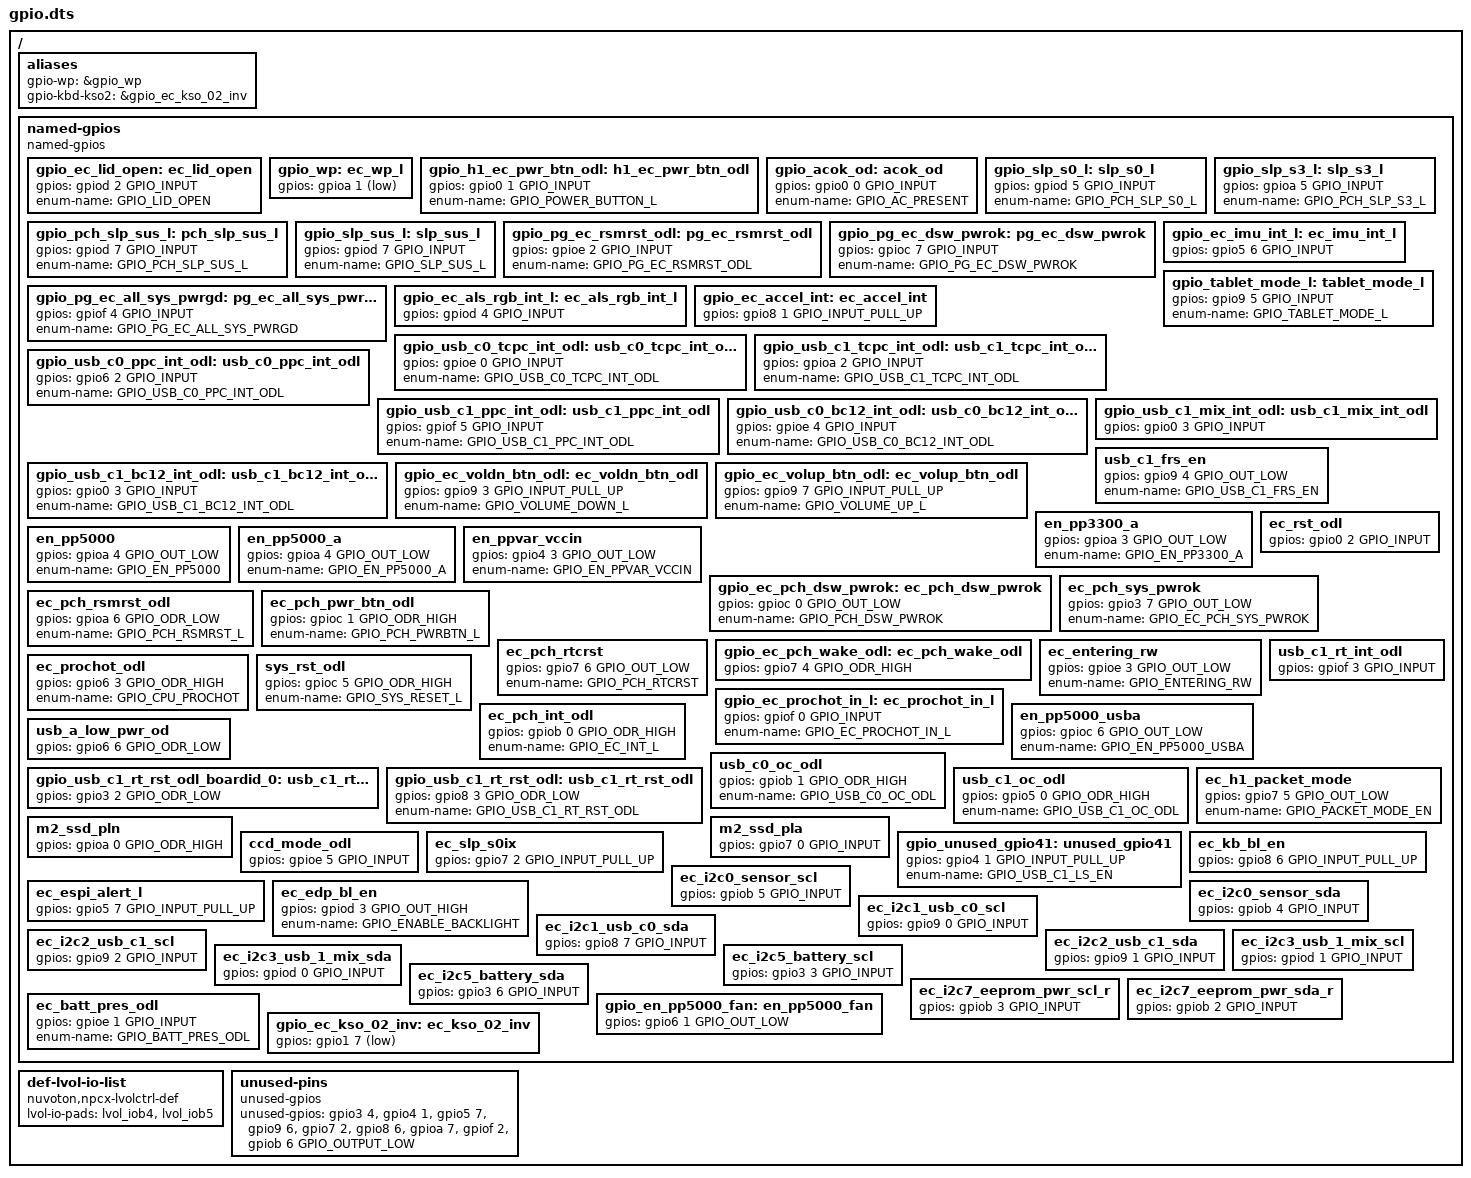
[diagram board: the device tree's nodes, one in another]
/* Copyright 2021 The Chromium OS Authors. All rights reserved.
 * Use of this source code is governed by a BSD-style license that can be
 * found in the LICENSE file.
 */

/ {
	aliases {
		gpio-wp = &gpio_wp;
		gpio-kbd-kso2 = &gpio_ec_kso_02_inv;
	};

	named-gpios {
		compatible = "named-gpios";

		gpio_ec_lid_open: ec_lid_open {
			gpios = <&gpiod 2 GPIO_INPUT>;
			enum-name = "GPIO_LID_OPEN";
		};
		gpio_wp: ec_wp_l {
			gpios = <&gpioa 1 (GPIO_INPUT | GPIO_ACTIVE_LOW)>;
		};
		gpio_h1_ec_pwr_btn_odl: h1_ec_pwr_btn_odl {
			gpios = <&gpio0 1 GPIO_INPUT>;
			enum-name = "GPIO_POWER_BUTTON_L";
		};
		gpio_acok_od: acok_od {
			gpios = <&gpio0 0 GPIO_INPUT>;
			enum-name = "GPIO_AC_PRESENT";
		};
		gpio_slp_s0_l: slp_s0_l {
			gpios = <&gpiod 5 GPIO_INPUT>;
			enum-name = "GPIO_PCH_SLP_S0_L";
		};
		gpio_slp_s3_l: slp_s3_l {
			gpios = <&gpioa 5 GPIO_INPUT>;
			enum-name = "GPIO_PCH_SLP_S3_L";
		};
		gpio_pch_slp_sus_l: pch_slp_sus_l {
			gpios = <&gpiod 7 GPIO_INPUT>;
			enum-name = "GPIO_PCH_SLP_SUS_L";
		};
		gpio_slp_sus_l: slp_sus_l {
			gpios = <&gpiod 7 GPIO_INPUT>;
			enum-name = "GPIO_SLP_SUS_L";
		};
		gpio_pg_ec_rsmrst_odl: pg_ec_rsmrst_odl {
			gpios = <&gpioe 2 GPIO_INPUT>;
			enum-name = "GPIO_PG_EC_RSMRST_ODL";
		};
		gpio_pg_ec_dsw_pwrok: pg_ec_dsw_pwrok {
			gpios = <&gpioc 7 GPIO_INPUT>;
			enum-name = "GPIO_PG_EC_DSW_PWROK";
		};
		gpio_pg_ec_all_sys_pwrgd: pg_ec_all_sys_pwrgd {
			gpios = <&gpiof 4 GPIO_INPUT>;
			enum-name = "GPIO_PG_EC_ALL_SYS_PWRGD";
		};
		gpio_ec_imu_int_l: ec_imu_int_l {
			gpios = <&gpio5 6 GPIO_INPUT>;
		};
		gpio_ec_als_rgb_int_l: ec_als_rgb_int_l {
			gpios = <&gpiod 4 GPIO_INPUT>;
		};
		gpio_tablet_mode_l: tablet_mode_l {
			gpios = <&gpio9 5 GPIO_INPUT>;
			enum-name = "GPIO_TABLET_MODE_L";
		};
		gpio_ec_accel_int: ec_accel_int {
			gpios = <&gpio8 1 GPIO_INPUT_PULL_UP>;
		};
		gpio_usb_c0_tcpc_int_odl: usb_c0_tcpc_int_odl {
			gpios = <&gpioe 0 GPIO_INPUT>;
			enum-name = "GPIO_USB_C0_TCPC_INT_ODL";
		};
		gpio_usb_c1_tcpc_int_odl: usb_c1_tcpc_int_odl {
			gpios = <&gpioa 2 GPIO_INPUT>;
			enum-name = "GPIO_USB_C1_TCPC_INT_ODL";
		};
		gpio_usb_c0_ppc_int_odl: usb_c0_ppc_int_odl {
			gpios = <&gpio6 2 GPIO_INPUT>;
			enum-name = "GPIO_USB_C0_PPC_INT_ODL";
		};
		gpio_usb_c1_ppc_int_odl: usb_c1_ppc_int_odl {
			gpios = <&gpiof 5 GPIO_INPUT>;
			enum-name = "GPIO_USB_C1_PPC_INT_ODL";
		};
		gpio_usb_c0_bc12_int_odl: usb_c0_bc12_int_odl {
			gpios = <&gpioe 4 GPIO_INPUT>;
			enum-name = "GPIO_USB_C0_BC12_INT_ODL";
		};
		gpio_usb_c1_mix_int_odl: usb_c1_mix_int_odl {
			gpios = <&gpio0 3 GPIO_INPUT>;
		};
		gpio_usb_c1_bc12_int_odl: usb_c1_bc12_int_odl {
			gpios = <&gpio0 3 GPIO_INPUT>;
			enum-name = "GPIO_USB_C1_BC12_INT_ODL";
		};
		usb_c1_frs_en {
			gpios = <&gpio9 4 GPIO_OUT_LOW>;
			enum-name = "GPIO_USB_C1_FRS_EN";
		};
		gpio_ec_voldn_btn_odl: ec_voldn_btn_odl {
			gpios = <&gpio9 3 GPIO_INPUT_PULL_UP>;
			enum-name = "GPIO_VOLUME_DOWN_L";
		};
		gpio_ec_volup_btn_odl: ec_volup_btn_odl {
			gpios = <&gpio9 7 GPIO_INPUT_PULL_UP>;
			enum-name = "GPIO_VOLUME_UP_L";
		};
		en_pp3300_a {
			gpios = <&gpioa 3 GPIO_OUT_LOW>;
			enum-name = "GPIO_EN_PP3300_A";
		};
		en_pp5000 {
			gpios = <&gpioa 4 GPIO_OUT_LOW>;
			enum-name = "GPIO_EN_PP5000";
		};
		en_pp5000_a {
			gpios = <&gpioa 4 GPIO_OUT_LOW>;
			enum-name = "GPIO_EN_PP5000_A";
		};
		en_ppvar_vccin {
			gpios = <&gpio4 3 GPIO_OUT_LOW>;
			enum-name = "GPIO_EN_PPVAR_VCCIN";
		};
		gpio_ec_pch_dsw_pwrok: ec_pch_dsw_pwrok {
			gpios = <&gpioc 0 GPIO_OUT_LOW>;
			enum-name = "GPIO_PCH_DSW_PWROK";
		};
		ec_rst_odl {
			gpios = <&gpio0 2 GPIO_INPUT>;
		};
		ec_pch_sys_pwrok {
			gpios = <&gpio3 7 GPIO_OUT_LOW>;
			enum-name = "GPIO_EC_PCH_SYS_PWROK";
		};
		ec_pch_rsmrst_odl {
			gpios = <&gpioa 6 GPIO_ODR_LOW>;
			enum-name = "GPIO_PCH_RSMRST_L";
		};
		ec_pch_pwr_btn_odl {
			gpios = <&gpioc 1 GPIO_ODR_HIGH>;
			enum-name = "GPIO_PCH_PWRBTN_L";
		};
		ec_pch_rtcrst {
			gpios = <&gpio7 6 GPIO_OUT_LOW>;
			enum-name = "GPIO_PCH_RTCRST";
		};
		gpio_ec_pch_wake_odl: ec_pch_wake_odl {
			gpios = <&gpio7 4 GPIO_ODR_HIGH>;
		};
		ec_entering_rw {
			gpios = <&gpioe 3 GPIO_OUT_LOW>;
			enum-name = "GPIO_ENTERING_RW";
		};
		ec_prochot_odl {
			gpios = <&gpio6 3 GPIO_ODR_HIGH>;
			enum-name = "GPIO_CPU_PROCHOT";
		};
		gpio_ec_prochot_in_l: ec_prochot_in_l {
			gpios = <&gpiof 0 GPIO_INPUT>;
			enum-name = "GPIO_EC_PROCHOT_IN_L";
		};
		sys_rst_odl {
			gpios = <&gpioc 5 GPIO_ODR_HIGH>;
			enum-name = "GPIO_SYS_RESET_L";
		};
		ec_pch_int_odl {
			gpios = <&gpiob 0 GPIO_ODR_HIGH>;
			enum-name = "GPIO_EC_INT_L";
		};
		en_pp5000_usba {
			gpios = <&gpioc 6 GPIO_OUT_LOW>;
			enum-name = "GPIO_EN_PP5000_USBA";
		};
		usb_a_low_pwr_od {
			gpios = <&gpio6 6 GPIO_ODR_LOW>;
		};
		gpio_usb_c1_rt_rst_odl_boardid_0: usb_c1_rt_rst_odl_boardid_0 {
			gpios = <&gpio3 2 GPIO_ODR_LOW>;
		};
		gpio_usb_c1_rt_rst_odl: usb_c1_rt_rst_odl {
			gpios = <&gpio8 3 GPIO_ODR_LOW>;
			enum-name = "GPIO_USB_C1_RT_RST_ODL";
		};
		usb_c0_oc_odl {
			gpios = <&gpiob 1 GPIO_ODR_HIGH>;
			enum-name = "GPIO_USB_C0_OC_ODL";
		};
		usb_c1_oc_odl {
			gpios = <&gpio5 0 GPIO_ODR_HIGH>;
			enum-name = "GPIO_USB_C1_OC_ODL";
		};
		usb_c1_rt_int_odl {
			gpios = <&gpiof 3 GPIO_INPUT>;
		};
		ec_h1_packet_mode {
			gpios = <&gpio7 5 GPIO_OUT_LOW>;
			enum-name = "GPIO_PACKET_MODE_EN";
		};
		m2_ssd_pln {
			gpios = <&gpioa 0 GPIO_ODR_HIGH>;
		};
		m2_ssd_pla {
			gpios = <&gpio7 0 GPIO_INPUT>;
		};
		ccd_mode_odl {
			gpios = <&gpioe 5 GPIO_INPUT>;
		};
		ec_slp_s0ix {
			gpios = <&gpio7 2 GPIO_INPUT_PULL_UP>;
		};
		gpio_unused_gpio41: unused_gpio41 {
			gpios = <&gpio4 1 GPIO_INPUT_PULL_UP>;
			enum-name = "GPIO_USB_C1_LS_EN";
		};
		ec_kb_bl_en {
			gpios = <&gpio8 6 GPIO_INPUT_PULL_UP>;
		};
		ec_espi_alert_l {
			gpios = <&gpio5 7 GPIO_INPUT_PULL_UP>;
		};
		ec_edp_bl_en {
			gpios = <&gpiod 3 GPIO_OUT_HIGH>;
			enum-name = "GPIO_ENABLE_BACKLIGHT";
		};
		ec_i2c0_sensor_scl {
			gpios = <&gpiob 5 GPIO_INPUT>;
		};
		ec_i2c0_sensor_sda {
			gpios = <&gpiob 4 GPIO_INPUT>;
		};
		ec_i2c1_usb_c0_scl {
			gpios = <&gpio9 0 GPIO_INPUT>;
		};
		ec_i2c1_usb_c0_sda {
			gpios = <&gpio8 7 GPIO_INPUT>;
		};
		ec_i2c2_usb_c1_scl {
			gpios = <&gpio9 2 GPIO_INPUT>;
		};
		ec_i2c2_usb_c1_sda {
			gpios = <&gpio9 1 GPIO_INPUT>;
		};
		ec_i2c3_usb_1_mix_scl {
			gpios = <&gpiod 1 GPIO_INPUT>;
		};
		ec_i2c3_usb_1_mix_sda {
			gpios = <&gpiod 0 GPIO_INPUT>;
		};
		ec_i2c5_battery_scl {
			gpios = <&gpio3 3 GPIO_INPUT>;
		};
		ec_i2c5_battery_sda {
			gpios = <&gpio3 6 GPIO_INPUT>;
		};
		ec_i2c7_eeprom_pwr_scl_r {
			gpios = <&gpiob 3 GPIO_INPUT>;
		};
		ec_i2c7_eeprom_pwr_sda_r {
			gpios = <&gpiob 2 GPIO_INPUT>;
		};
		/*
		 * TODO(b:190743662) Cleanup to possibly remove the enum
		 */
		ec_batt_pres_odl {
			gpios = <&gpioe 1 GPIO_INPUT>;
			enum-name = "GPIO_BATT_PRES_ODL";
		};
		gpio_en_pp5000_fan: en_pp5000_fan {
			gpios = <&gpio6 1 GPIO_OUT_LOW>;
		};
		gpio_ec_kso_02_inv: ec_kso_02_inv {
			gpios = <&gpio1 7 (GPIO_OUT_LOW | GPIO_ACTIVE_LOW)>;
		};
	};

	def-lvol-io-list {
		compatible = "nuvoton,npcx-lvolctrl-def";
		lvol-io-pads = <&lvol_iob4 &lvol_iob5>; /* I2C_SDA0 & SCL0 */
	};

	unused-pins {
		compatible = "unused-gpios";
		unused-gpios =
			<&gpio3 4 0>,
			<&gpio4 1 0>,
			<&gpio5 7 0>, /* EC_ESPI_ALERT_L not stuffed */
			<&gpio9 6 0>,
			<&gpio7 2 0>, /* EC_SLP_S0IX not stuffed */
			<&gpio8 6 0>, /* EC_KB_BL_EN not stuffed */
			<&gpioa 7 0>, /* EN_PP5000_USB_AG not stuffed */
			<&gpiof 2 0>,
			/*
			 * GPIOB6 cannot be configured as an input.
			 * Drive output low so signal level doesn't
			 * depend on default setting of PxDOUT register.
			 */
			 <&gpiob 6 GPIO_OUTPUT_LOW>;
	};
};
